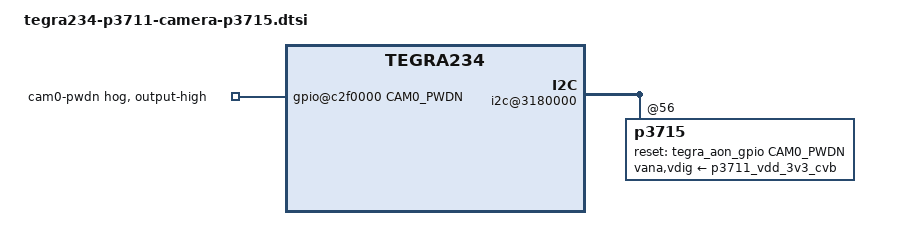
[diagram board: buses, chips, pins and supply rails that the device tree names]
/*
 * Copyright (c) 2021, NVIDIA CORPORATION.  All rights reserved.
 *
 * This program is free software; you can redistribute it and/or modify
 * it under the terms of the GNU General Public License as published by
 * the Free Software Foundation; version 2 of the License.
 *
 * This program is distributed in the hope that it will be useful, but WITHOUT
 * ANY WARRANTY; without even the implied warranty of MERCHANTABILITY or
 * FITNESS FOR A PARTICULAR PURPOSE.  See the GNU General Public License for
 * more details.
 */

#include "tegra234-camera-p3715.dtsi"

#define CAM0_PWDN	TEGRA234_AON_GPIO(AA, 4)
#define CAMERA_I2C_MUX_BUS(x) (0x1E + x)

/ {

	i2c@3180000 {
		p3715@56 {
			/* Define any required hw resources needed by driver */
			/* ie. clocks, io pins, power sources */
			clocks = <&bpmp_clks TEGRA234_CLK_EXTPERIPH1>,
				<&bpmp_clks TEGRA234_CLK_EXTPERIPH1>;
			clock-names = "extperiph1", "pllp_grtba";
			mclk = "extperiph1";
			reset-gpios = <&tegra_aon_gpio CAM0_PWDN GPIO_ACTIVE_HIGH>;
			vana-supply = <&p3711_vdd_3v3_cvb>;
			vdig-supply = <&p3711_vdd_3v3_cvb>;
		};
	};
	gpio@c2f0000 {
		camera-control-output-high {
			gpio-hog;
			output-high;
			gpios = <CAM0_PWDN 0>;
			label = "cam0-pwdn";
		};
	};
};
